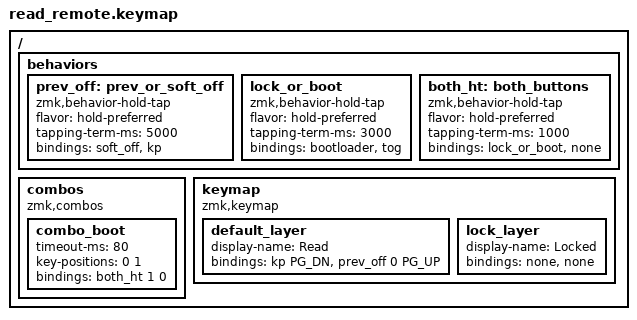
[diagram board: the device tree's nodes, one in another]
#include <behaviors.dtsi>
#include <dt-bindings/zmk/keys.h>

/*
 * Key 0 = NEXT (big dished cap, far end, wired to D0)
 * Key 1 = PREV (small domed cap, wired to D1)
 *
 * Page Down / Page Up: KOReader maps these to next/previous page (as do most
 * reader apps). Remap in ZMK Studio or edit the bindings below.
 *
 * Hold PREV 5 s        = power off (any press wakes)
 * Hold NEXT+PREV 1-4 s = travel lock on/off (buttons ignored while locked)
 * Hold NEXT+PREV 4 s+  = reboot into the UF2 bootloader for flashing
 */

/ {
    behaviors {
        prev_off: prev_or_soft_off {
            compatible = "zmk,behavior-hold-tap";
            #binding-cells = <2>;
            flavor = "hold-preferred";
            tapping-term-ms = <5000>;   // tap = PREV, hold 5 s = power off
            bindings = <&soft_off>, <&kp>;
        };
        // Both buttons: tap = nothing, hold 1-4 s = travel lock on/off, hold 4 s+ = UF2 bootloader
        lock_or_boot: lock_or_boot {
            compatible = "zmk,behavior-hold-tap";
            #binding-cells = <2>;
            flavor = "hold-preferred";
            tapping-term-ms = <3000>;
            bindings = <&bootloader>, <&tog>;
        };
        both_ht: both_buttons {
            compatible = "zmk,behavior-hold-tap";
            #binding-cells = <2>;
            flavor = "hold-preferred";
            tapping-term-ms = <1000>;
            bindings = <&lock_or_boot>, <&none>;
        };
    };

    combos {
        compatible = "zmk,combos";
        combo_boot {
            timeout-ms = <80>;
            key-positions = <0 1>;
            bindings = <&both_ht 1 0>;   // param 1 = the lock layer
        };
    };

    keymap {
        compatible = "zmk,keymap";

        default_layer {
            display-name = "Read";
            bindings = <&kp PG_DN   &prev_off 0 PG_UP>;
        };

        lock_layer {   // travel lock: buttons do nothing; the both-buttons combo still works to unlock
            display-name = "Locked";
            bindings = <&none   &none>;
        };
    };
};
